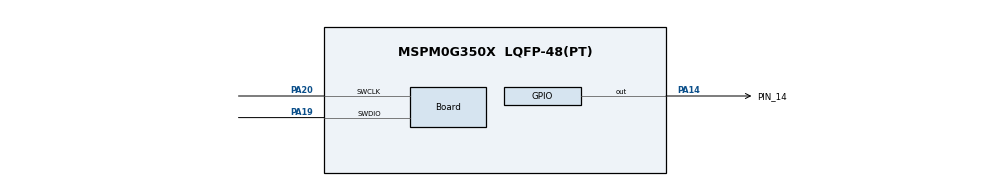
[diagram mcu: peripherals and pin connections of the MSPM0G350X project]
/**
 * @cliArgs --device "MSPM0G350X" --package "LQFP-48(PT)" --part "Default" --product "mspm0_sdk@2.01.00.03"
 * @versions {"tool":"1.20.0+3587"}
 */

/**
 * Import the modules used in this configuration.
 */
const GPIO          = scripting.addModule("/ti/driverlib/GPIO", {}, false);
const GPIO1         = GPIO.addInstance();
const SYSCTL        = scripting.addModule("/ti/driverlib/SYSCTL");
const TIMER         = scripting.addModule("/ti/driverlib/TIMER", {}, false);
const TIMER1        = TIMER.addInstance();
const ProjectConfig = scripting.addModule("/ti/project_config/ProjectConfig");

/**
 * Write custom configuration values to the imported modules.
 */
GPIO1.$name                              = "LED";
GPIO1.port                               = "PORTA";
GPIO1.associatedPins[0].$name            = "PIN_14";
GPIO1.associatedPins[0].internalResistor = "PULL_UP";
GPIO1.associatedPins[0].assignedPin      = "14";
GPIO1.associatedPins[0].pin.$assign      = "PA14";

const Board                       = scripting.addModule("/ti/driverlib/Board", {}, false);
Board.peripheral.$assign          = "DEBUGSS";
Board.peripheral.swclkPin.$assign = "PA20";
Board.peripheral.swdioPin.$assign = "PA19";

SYSCTL.forceDefaultClkConfig = true;
SYSCTL.peripheral.$assign    = "SYSCTL";

TIMER1.$name              = "TIMER_0";
TIMER1.timerClkDiv        = 8;
TIMER1.timerClkPrescale   = 100;
TIMER1.timerMode          = "PERIODIC";
TIMER1.timerPeriod        = "1000ms";
TIMER1.timerStartTimer    = true;
TIMER1.interrupts         = ["ZERO"];
TIMER1.peripheral.$assign = "TIMG0";

ProjectConfig.deviceSpin = "MSPM0G3507";
scripting.suppress("Migrating requires going through the Switch Board or Device menu in the Device View section\\.", ProjectConfig, "deviceSpin");
